# SDIO2 register map
Registers from a debugger description file.
Registers are 16-bit, access not given, no defined reset value unless marked. A register's access mark holds for its fields unless they carry their own. Addresses are absolute; registers are grouped by the start of their names; lines under a group give offsets from that group; [hi:lo] are bit positions; {n}, {i} and the like mark numbered series; 'fields as' and 'values as' point back to an identical list; <NAME> marks a mode.

## SDIO2
0x40101000 SDIO2/sdmasysaddrlo
  [15:0] sdma_sysaddress
0x40101002 SDIO2/sdmasysaddrhi
  [15:0] sdma_sysaddress
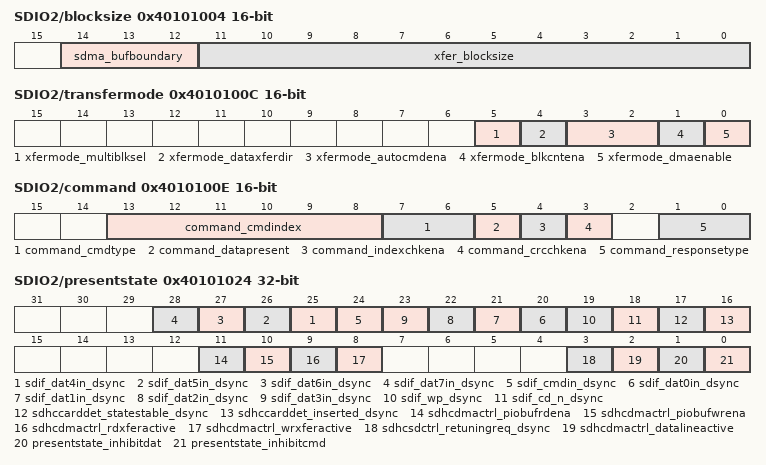
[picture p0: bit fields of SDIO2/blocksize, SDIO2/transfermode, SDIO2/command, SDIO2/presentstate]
0x40101004 SDIO2/blocksize
  [14:12] sdma_bufboundary, [11:0] xfer_blocksize
0x40101006 SDIO2/blockcount
  [15:0] xfer_blockcount
0x40101008 SDIO2/argument1lo
  [15:0] command_argument1
0x4010100A SDIO2/argument1hi
  [15:0] command_argument1
0x4010100C SDIO2/transfermode
  [5] xfermode_multiblksel, [4] xfermode_dataxferdir, [3:2] xfermode_autocmdena, [1] xfermode_blkcntena, [0] xfermode_dmaenable
0x4010100E SDIO2/command
  [13:8] command_cmdindex, [7:6] command_cmdtype, [5] command_datapresent, [4] command_indexchkena, [3] command_crcchkena, [1:0] command_responsetype
{0x40101010+2i} SDIO2/response{i} ro (i=0..7)
  [15:0] command_response
0x40101020 SDIO2/dataport 32-bit
  [31:0] sdhcdmactrl_piobufrddata
0x40101024 SDIO2/presentstate 32-bit ro
  [n+21] sdif_dat{n}in_dsync (n=4..7), [24] sdif_cmdin_dsync, [n+20] sdif_dat{n}in_dsync (n=0..3), [19] sdif_wp_dsync, [18] sdif_cd_n_dsync, [17] sdhccarddet_statestable_dsync, [16] sdhccarddet_inserted_dsync, [11] sdhcdmactrl_piobufrdena, [10] sdhcdmactrl_piobufwrena, [9] sdhcdmactrl_rdxferactive, [8] sdhcdmactrl_wrxferactive, [3] sdhcsdctrl_retuningreq_dsync, [2] sdhcdmactrl_datalineactive, [1] presentstate_inhibitdat, [0] presentstate_inhibitcmd
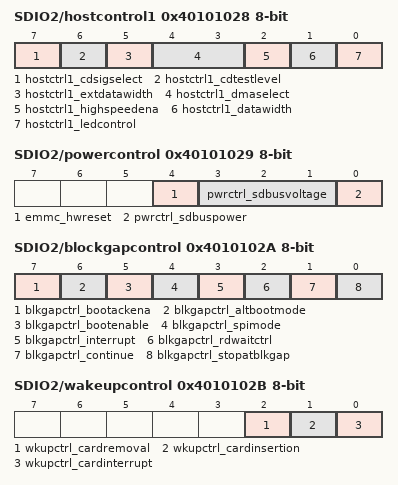
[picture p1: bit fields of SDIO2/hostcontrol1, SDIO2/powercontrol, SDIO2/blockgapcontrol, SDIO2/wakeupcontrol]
0x40101028 SDIO2/hostcontrol1 8-bit
  [7] hostctrl1_cdsigselect, [6] hostctrl1_cdtestlevel, [5] hostctrl1_extdatawidth, [4:3] hostctrl1_dmaselect, [2] hostctrl1_highspeedena, [1] hostctrl1_datawidth, [0] hostctrl1_ledcontrol
0x40101029 SDIO2/powercontrol 8-bit
  [4] emmc_hwreset, [3:1] pwrctrl_sdbusvoltage, [0] pwrctrl_sdbuspower
0x4010102A SDIO2/blockgapcontrol 8-bit
  [7] blkgapctrl_bootackena, [6] blkgapctrl_altbootmode, [5] blkgapctrl_bootenable, [4] blkgapctrl_spimode, [3] blkgapctrl_interrupt, [2] blkgapctrl_rdwaitctrl, [1] blkgapctrl_continue, [0] blkgapctrl_stopatblkgap
0x4010102B SDIO2/wakeupcontrol 8-bit
  [2] wkupctrl_cardremoval, [1] wkupctrl_cardinsertion, [0] wkupctrl_cardinterrupt
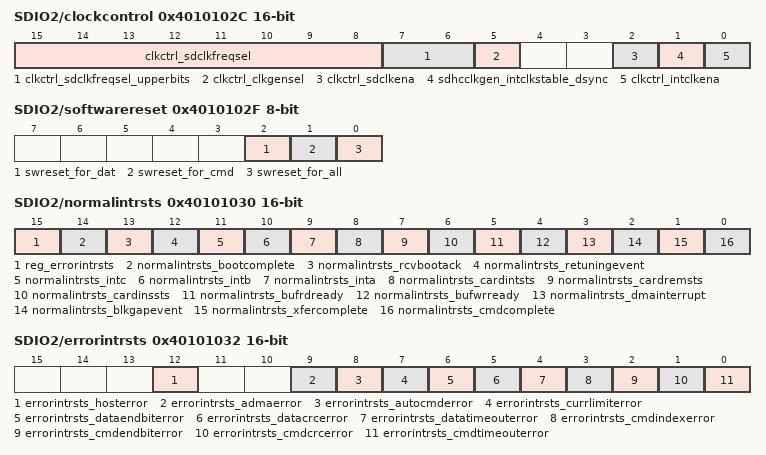
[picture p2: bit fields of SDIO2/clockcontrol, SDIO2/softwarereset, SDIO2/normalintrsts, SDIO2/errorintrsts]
0x4010102C SDIO2/clockcontrol
  [15:8] clkctrl_sdclkfreqsel, [7:6] clkctrl_sdclkfreqsel_upperbits, [5] clkctrl_clkgensel, [2] clkctrl_sdclkena, [1] sdhcclkgen_intclkstable_dsync, [0] clkctrl_intclkena
0x4010102E SDIO2/timeoutcontrol 8-bit
  [3:0] timeout_ctrvalue
0x4010102F SDIO2/softwarereset 8-bit
  [2] swreset_for_dat, [1] swreset_for_cmd, [0] swreset_for_all
0x40101030 SDIO2/normalintrsts
  [15] reg_errorintrsts, [14] normalintrsts_bootcomplete, [13] normalintrsts_rcvbootack, [12] normalintrsts_retuningevent, [11] normalintrsts_intc, [10] normalintrsts_intb, [9] normalintrsts_inta, [8] normalintrsts_cardintsts, [7] normalintrsts_cardremsts, [6] normalintrsts_cardinssts, [5] normalintrsts_bufrdready, [4] normalintrsts_bufwrready, [3] normalintrsts_dmainterrupt, [2] normalintrsts_blkgapevent, [1] normalintrsts_xfercomplete, [0] normalintrsts_cmdcomplete
0x40101032 SDIO2/errorintrsts
  [12] errorintrsts_hosterror, [9] errorintrsts_admaerror, [8] errorintrsts_autocmderror, [7] errorintrsts_currlimiterror, [6] errorintrsts_dataendbiterror, [5] errorintrsts_datacrcerror, [4] errorintrsts_datatimeouterror, [3] errorintrsts_cmdindexerror, [2] errorintrsts_cmdendbiterror, [1] errorintrsts_cmdcrcerror, [0] errorintrsts_cmdtimeouterror
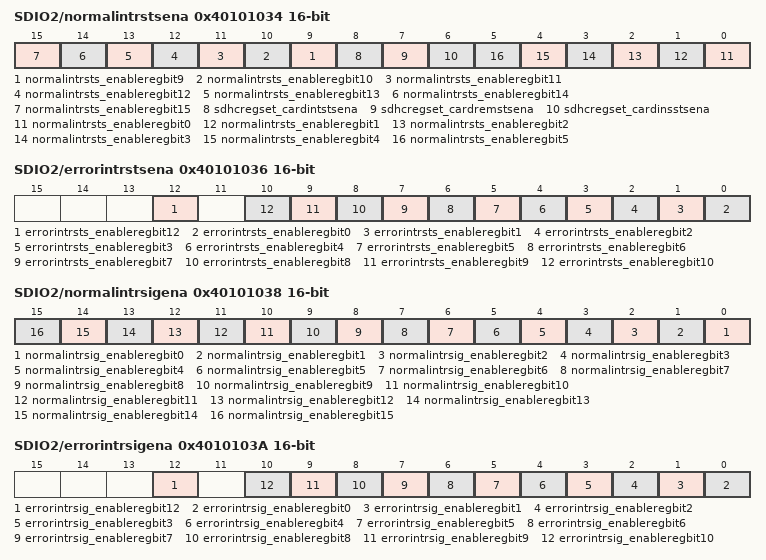
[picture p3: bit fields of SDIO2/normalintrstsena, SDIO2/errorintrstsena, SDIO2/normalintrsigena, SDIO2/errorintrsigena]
0x40101034 SDIO2/normalintrstsena
  [n] normalintrsts_enableregbit{n} (n=9..15), [8] sdhcregset_cardintstsena, [7] sdhcregset_cardremstsena, [6] sdhcregset_cardinsstsena, [n] normalintrsts_enableregbit{n} (n=0..5)
0x40101036 SDIO2/errorintrstsena
  [12] errorintrsts_enableregbit12, [n] errorintrsts_enableregbit{n} (n=0..10)
0x40101038 SDIO2/normalintrsigena
  [n] normalintrsig_enableregbit{n} (n=0..15)
0x4010103A SDIO2/errorintrsigena
  [12] errorintrsig_enableregbit12, [n] errorintrsig_enableregbit{n} (n=0..10)
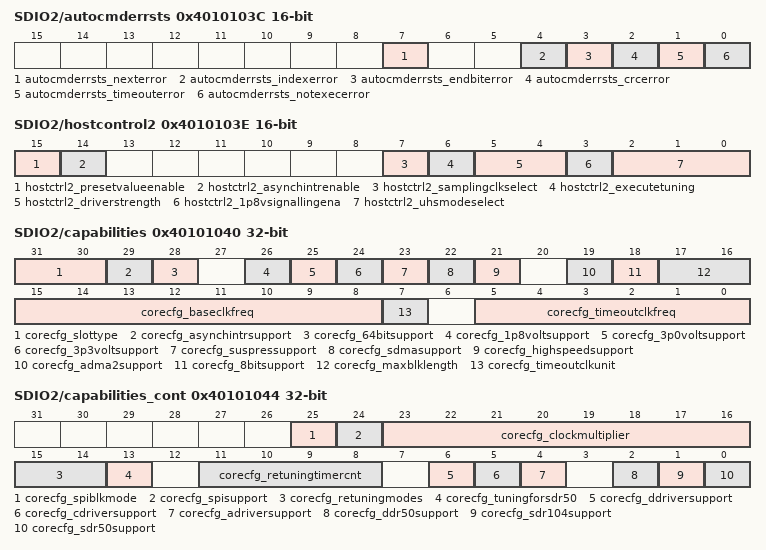
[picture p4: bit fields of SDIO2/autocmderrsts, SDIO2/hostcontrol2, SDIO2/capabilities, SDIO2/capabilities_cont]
0x4010103C SDIO2/autocmderrsts ro
  [7] autocmderrsts_nexterror, [4] autocmderrsts_indexerror, [3] autocmderrsts_endbiterror, [2] autocmderrsts_crcerror, [1] autocmderrsts_timeouterror, [0] autocmderrsts_notexecerror
0x4010103E SDIO2/hostcontrol2
  [15] hostctrl2_presetvalueenable, [14] hostctrl2_asynchintrenable, [7] hostctrl2_samplingclkselect, [6] hostctrl2_executetuning, [5:4] hostctrl2_driverstrength, [3] hostctrl2_1p8vsignallingena, [2:0] hostctrl2_uhsmodeselect
0x40101040 SDIO2/capabilities 32-bit ro
  [31:30] corecfg_slottype, [29] corecfg_asynchintrsupport, [28] corecfg_64bitsupport, [26] corecfg_1p8voltsupport, [25] corecfg_3p0voltsupport, [24] corecfg_3p3voltsupport, [23] corecfg_suspressupport, [22] corecfg_sdmasupport, [21] corecfg_highspeedsupport, [19] corecfg_adma2support, [18] corecfg_8bitsupport, [17:16] corecfg_maxblklength, [15:8] corecfg_baseclkfreq, [7] corecfg_timeoutclkunit, [5:0] corecfg_timeoutclkfreq
0x40101044 SDIO2/capabilities_cont 32-bit ro
  [25] corecfg_spiblkmode, [24] corecfg_spisupport, [23:16] corecfg_clockmultiplier, [15:14] corecfg_retuningmodes, [13] corecfg_tuningforsdr50, [11:8] corecfg_retuningtimercnt, [6] corecfg_ddriversupport, [5] corecfg_cdriversupport, [4] corecfg_adriversupport, [2] corecfg_ddr50support, [1] corecfg_sdr104support, [0] corecfg_sdr50support
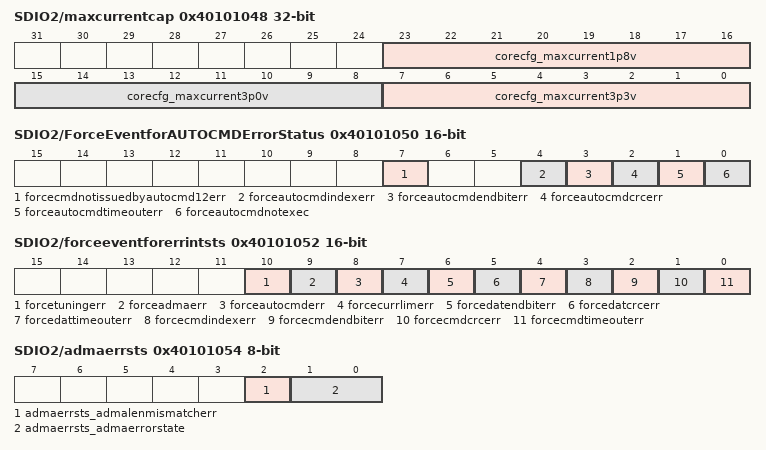
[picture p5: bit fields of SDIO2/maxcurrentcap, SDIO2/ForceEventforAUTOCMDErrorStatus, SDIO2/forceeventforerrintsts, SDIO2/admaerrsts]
0x40101048 SDIO2/maxcurrentcap 32-bit ro
  [23:16] corecfg_maxcurrent1p8v, [15:8] corecfg_maxcurrent3p0v, [7:0] corecfg_maxcurrent3p3v
0x4010104C SDIO2/maxcurrentcap_cont 32-bit ro
0x40101050 SDIO2/ForceEventforAUTOCMDErrorStatus wo
  [7] forcecmdnotissuedbyautocmd12err, [4] forceautocmdindexerr, [3] forceautocmdendbiterr, [2] forceautocmdcrcerr, [1] forceautocmdtimeouterr, [0] forceautocmdnotexec
0x40101052 SDIO2/forceeventforerrintsts wo
  [10] forcetuningerr, [9] forceadmaerr, [8] forceautocmderr, [7] forcecurrlimerr, [6] forcedatendbiterr, [5] forcedatcrcerr, [4] forcedattimeouterr, [3] forcecmdindexerr, [2] forcecmdendbiterr, [1] forcecmdcrcerr, [0] forcecmdtimeouterr
0x40101054 SDIO2/admaerrsts 8-bit ro
  [2] admaerrsts_admalenmismatcherr, [1:0] admaerrsts_admaerrorstate
{0x40101058+2i} SDIO2/admasysaddr{i} (i=0..3)
  [15:0] adma_sysaddress{i}
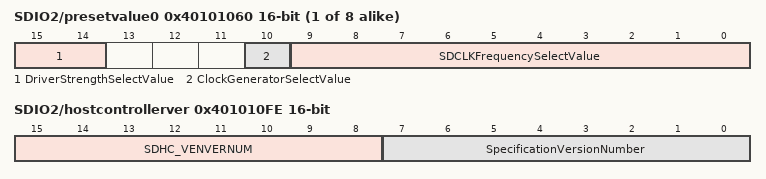
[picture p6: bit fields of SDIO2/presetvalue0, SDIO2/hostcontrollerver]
{0x40101060+2i} SDIO2/presetvalue{i} ro (i=0..7)
  [15:14] DriverStrengthSelectValue, [10] ClockGeneratorSelectValue, [9:0] SDCLKFrequencySelectValue
0x40101070 SDIO2/boottimeoutcnt 32-bit
  [31:0] boot_timeoutcnt
0x401010FC SDIO2/slotintrsts ro
  [7:0] sdhchostif_slotintrsts
0x401010FE SDIO2/hostcontrollerver ro
  [15:8] SDHC_VENVERNUM, [7:0] SpecificationVersionNumber
